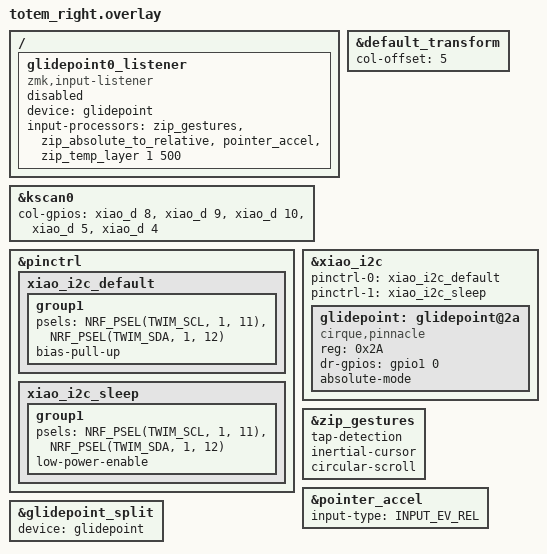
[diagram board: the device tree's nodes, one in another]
/*
 * Copyright (c) 2022 The ZMK Contributors
 *
 * SPDX-License-Identifier: MIT
 */

#include "totem.dtsi"
#include <dt-bindings/input/input-event-codes.h>
#include <input/processors.dtsi>
#include <behaviors/input_processor_gestures.dtsi>
#include <behaviors/input_processor_absolute_to_relative.dtsi>
#include <dt-bindings/zmk/input_transform.h>
#include <behaviors/input_gestures_accel.dtsi>

&default_transform {
    col-offset = <5>;
};

&kscan0 {
    col-gpios
        = <&xiao_d 8 GPIO_ACTIVE_HIGH>
        , <&xiao_d 9 GPIO_ACTIVE_HIGH>
        , <&xiao_d 10 GPIO_ACTIVE_HIGH>
        , <&xiao_d 5 GPIO_ACTIVE_HIGH>
        , <&xiao_d 4 GPIO_ACTIVE_HIGH>
        ;
};

&pinctrl {
    xiao_i2c_default: xiao_i2c_default {
        group1 {
            psels = <NRF_PSEL(TWIM_SCL, 1, 11)>, <NRF_PSEL(TWIM_SDA, 1, 12)>;
            bias-pull-up;
        };
    };
    xiao_i2c_sleep: xiao_i2c_sleep {
        group1 {
            psels = <NRF_PSEL(TWIM_SCL, 1, 11)>, <NRF_PSEL(TWIM_SDA, 1, 12)>;
            low-power-enable;
        };
    };
};

&xiao_i2c {
    status = "okay";
    pinctrl-0 = <&xiao_i2c_default>;
    pinctrl-1 = <&xiao_i2c_sleep>;
    pinctrl-names = "default", "sleep";

    glidepoint: glidepoint@2a {
        compatible = "cirque,pinnacle";
        reg = <0x2A>;
        status = "okay";
        dr-gpios = <&gpio1 0 GPIO_ACTIVE_HIGH>;

        absolute-mode;
    };
};


&zip_gestures {
    // https://github.com/halfdane/zmk-input-gestures

    tap-detection;
    inertial-cursor;
    circular-scroll;
};

&pointer_accel {
    input-type = <INPUT_EV_REL>;
};

&glidepoint {
	status = "okay";
};

// Cirque Trackpad, if the Left side is central, comment otherwise

&glidepoint_split {
	device = <&glidepoint>;
};

/ {
    glidepoint0_listener: glidepoint0_listener {
        compatible = "zmk,input-listener";
        status = "disabled";
        device = <&glidepoint>;
        input-processors = <
            &zip_gestures
            &zip_absolute_to_relative
            &pointer_accel
            &zip_temp_layer 1 500
	    >;
    };
};
